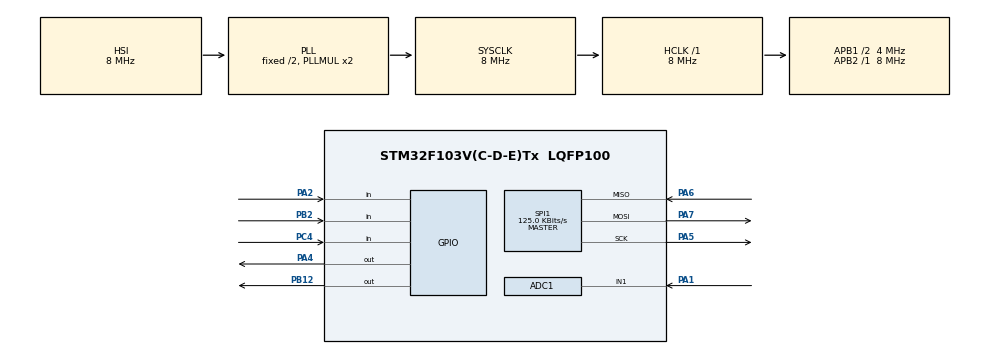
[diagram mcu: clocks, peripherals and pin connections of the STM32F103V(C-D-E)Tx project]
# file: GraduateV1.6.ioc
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ADC1.Channel-0\#ChannelRegularConversion=ADC_CHANNEL_1
ADC1.NbrOfConversionFlag=1
ADC1.Rank-0\#ChannelRegularConversion=1
ADC1.SamplingTime-0\#ChannelRegularConversion=ADC_SAMPLETIME_1CYCLE_5
ADC1.master=1
Mcu.Family=STM32F1
Mcu.Name=STM32F103V(C-D-E)Tx
Mcu.Package=LQFP100
NVIC.ADC1_2_IRQn=true\:0\:0\:false\:false\:true\:true\:true
NVIC.PriorityGroup=NVIC_PRIORITYGROUP_4
NVIC.TIM2_IRQn=true\:1\:0\:true\:false\:true\:true\:true
NVIC.TIM6_IRQn=true\:2\:0\:true\:false\:true\:true\:true
OSC_IN.Mode=HSE-External-Oscillator
OSC_IN.Signal=RCC_OSC_IN
OSC_OUT.Mode=HSE-External-Oscillator
OSC_OUT.Signal=RCC_OSC_OUT
PA1.Signal=ADCx_IN1
PA10.Signal=USART1_RX
PA13.Mode=Serial_Wire
PA13.Signal=SYS_JTMS-SWDIO
PA14.Mode=Serial_Wire
PA14.Signal=SYS_JTCK-SWCLK
PA2.Signal=GPIO_Input
PA4.GPIO_Speed=GPIO_SPEED_FREQ_MEDIUM
PA4.PinState=GPIO_PIN_RESET
PA4.Signal=GPIO_Output
PA5.Mode=Full_Duplex_Master
PA5.Signal=SPI1_SCK
PA6.Mode=Full_Duplex_Master
PA6.Signal=SPI1_MISO
PA7.Mode=Full_Duplex_Master
PA7.Signal=SPI1_MOSI
PA9.Signal=USART1_TX
PB12.Signal=GPIO_Output
PB2.Signal=GPIO_Input
PC4.Signal=GPIO_Input
ProjectManager.HeapSize=0x200
ProjectManager.StackSize=0x400
ProjectManager.TargetToolchain=STM32CubeIDE
RCC.AHBFreq_Value=8000000
RCC.APB1CLKDivider=RCC_HCLK_DIV2
RCC.APB1Freq_Value=4000000
RCC.APB1TimFreq_Value=8000000
RCC.APB2Freq_Value=8000000
RCC.APB2TimFreq_Value=8000000
RCC.HCLKFreq_Value=8000000
RCC.SYSCLKFreq_VALUE=8000000
RCC.SYSCLKSource=RCC_SYSCLKSOURCE_PLLCLK
RCC.USBFreq_Value=8000000
SH.ADCx_IN1.0=ADC1_IN1,IN1
SPI1.BaudRatePrescaler=SPI_BAUDRATEPRESCALER_64
SPI1.CalculateBaudRate=125.0 KBits/s
SPI1.Direction=SPI_DIRECTION_2LINES
SPI1.Mode=SPI_MODE_MASTER
SPI1.VirtualType=VM_MASTER
TIM2.AutoReloadPreload=TIM_AUTORELOAD_PRELOAD_ENABLE
TIM2.Period=999
TIM2.Prescaler=7
TIM6.Period=31000
TIM6.Prescaler=79
VP_TIM2_VS_ClockSourceINT.Mode=Internal
VP_TIM6_VS_ClockSourceINT.Mode=Enable_Timer
board=custom

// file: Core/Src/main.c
/* USER CODE BEGIN Header */
/**
  ******************************************************************************
  * @file           : main.c
  * @brief          : Main program body
  ******************************************************************************
  * @attention
  *
  * <h2><center>&copy; Copyright (c) 2021 STMicroelectronics.
  * All rights reserved.</center></h2>
  *
  * This software component is licensed by ST under BSD 3-Clause license,
  * the "License"; You may not use this file except in compliance with the
  * License. You may obtain a copy of the License at:
  *                        opensource.org/licenses/BSD-3-Clause
  *
  ******************************************************************************
  */
/* USER CODE END Header */
#include "main.h"
#include "adc.h"
#include "spi.h"
#include "tim.h"
#include "gpio.h"

/* USER CODE BEGIN Includes */
#include "App_Test.h"

/* USER CODE END Includes */

void SystemClock_Config(void);

int main(void)
{

  /* MCU Configuration--------------------------------------------------------*/

  /* Reset of all peripherals, Initializes the Flash interface and the Systick. */
  HAL_Init();

  /* Configure the system clock */
  SystemClock_Config();

  /* Initialize all configured peripherals */
  MX_GPIO_Init();
  MX_ADC1_Init();
  MX_SPI1_Init();
  MX_TIM2_Init();
  MX_TIM6_Init();

  /* Infinite loop */
  /* USER CODE BEGIN WHILE */
  while (1)
  {
	  App_TestMain();
    /* USER CODE END WHILE */

  }
}

void SystemClock_Config(void)
{
  RCC_OscInitTypeDef RCC_OscInitStruct = {0};
  RCC_ClkInitTypeDef RCC_ClkInitStruct = {0};
  RCC_PeriphCLKInitTypeDef PeriphClkInit = {0};

  /** Initializes the RCC Oscillators according to the specified parameters
  * in the RCC_OscInitTypeDef structure.
  */
  RCC_OscInitStruct.OscillatorType = RCC_OSCILLATORTYPE_HSI;
  RCC_OscInitStruct.HSIState = RCC_HSI_ON;
  RCC_OscInitStruct.HSICalibrationValue = RCC_HSICALIBRATION_DEFAULT;
  RCC_OscInitStruct.PLL.PLLState = RCC_PLL_ON;
  RCC_OscInitStruct.PLL.PLLSource = RCC_PLLSOURCE_HSI_DIV2;
  RCC_OscInitStruct.PLL.PLLMUL = RCC_PLL_MUL2;
  if (HAL_RCC_OscConfig(&RCC_OscInitStruct) != HAL_OK)
  {
    Error_Handler();
  }
  /** Initializes the CPU, AHB and APB buses clocks
  */
  RCC_ClkInitStruct.ClockType = RCC_CLOCKTYPE_HCLK|RCC_CLOCKTYPE_SYSCLK
                              |RCC_CLOCKTYPE_PCLK1|RCC_CLOCKTYPE_PCLK2;
  RCC_ClkInitStruct.SYSCLKSource = RCC_SYSCLKSOURCE_PLLCLK;
  RCC_ClkInitStruct.AHBCLKDivider = RCC_SYSCLK_DIV1;
  RCC_ClkInitStruct.APB1CLKDivider = RCC_HCLK_DIV2;
  RCC_ClkInitStruct.APB2CLKDivider = RCC_HCLK_DIV1;

  if (HAL_RCC_ClockConfig(&RCC_ClkInitStruct, FLASH_LATENCY_0) != HAL_OK)
  {
    Error_Handler();
  }
  PeriphClkInit.PeriphClockSelection = RCC_PERIPHCLK_ADC;
  PeriphClkInit.AdcClockSelection = RCC_ADCPCLK2_DIV2;
  if (HAL_RCCEx_PeriphCLKConfig(&PeriphClkInit) != HAL_OK)
  {
    Error_Handler();
  }
}

void Error_Handler(void)
{
  __disable_irq();
  while (1)
  {
  }
}

/************************ (C) COPYRIGHT STMicroelectronics *****END OF FILE****/
